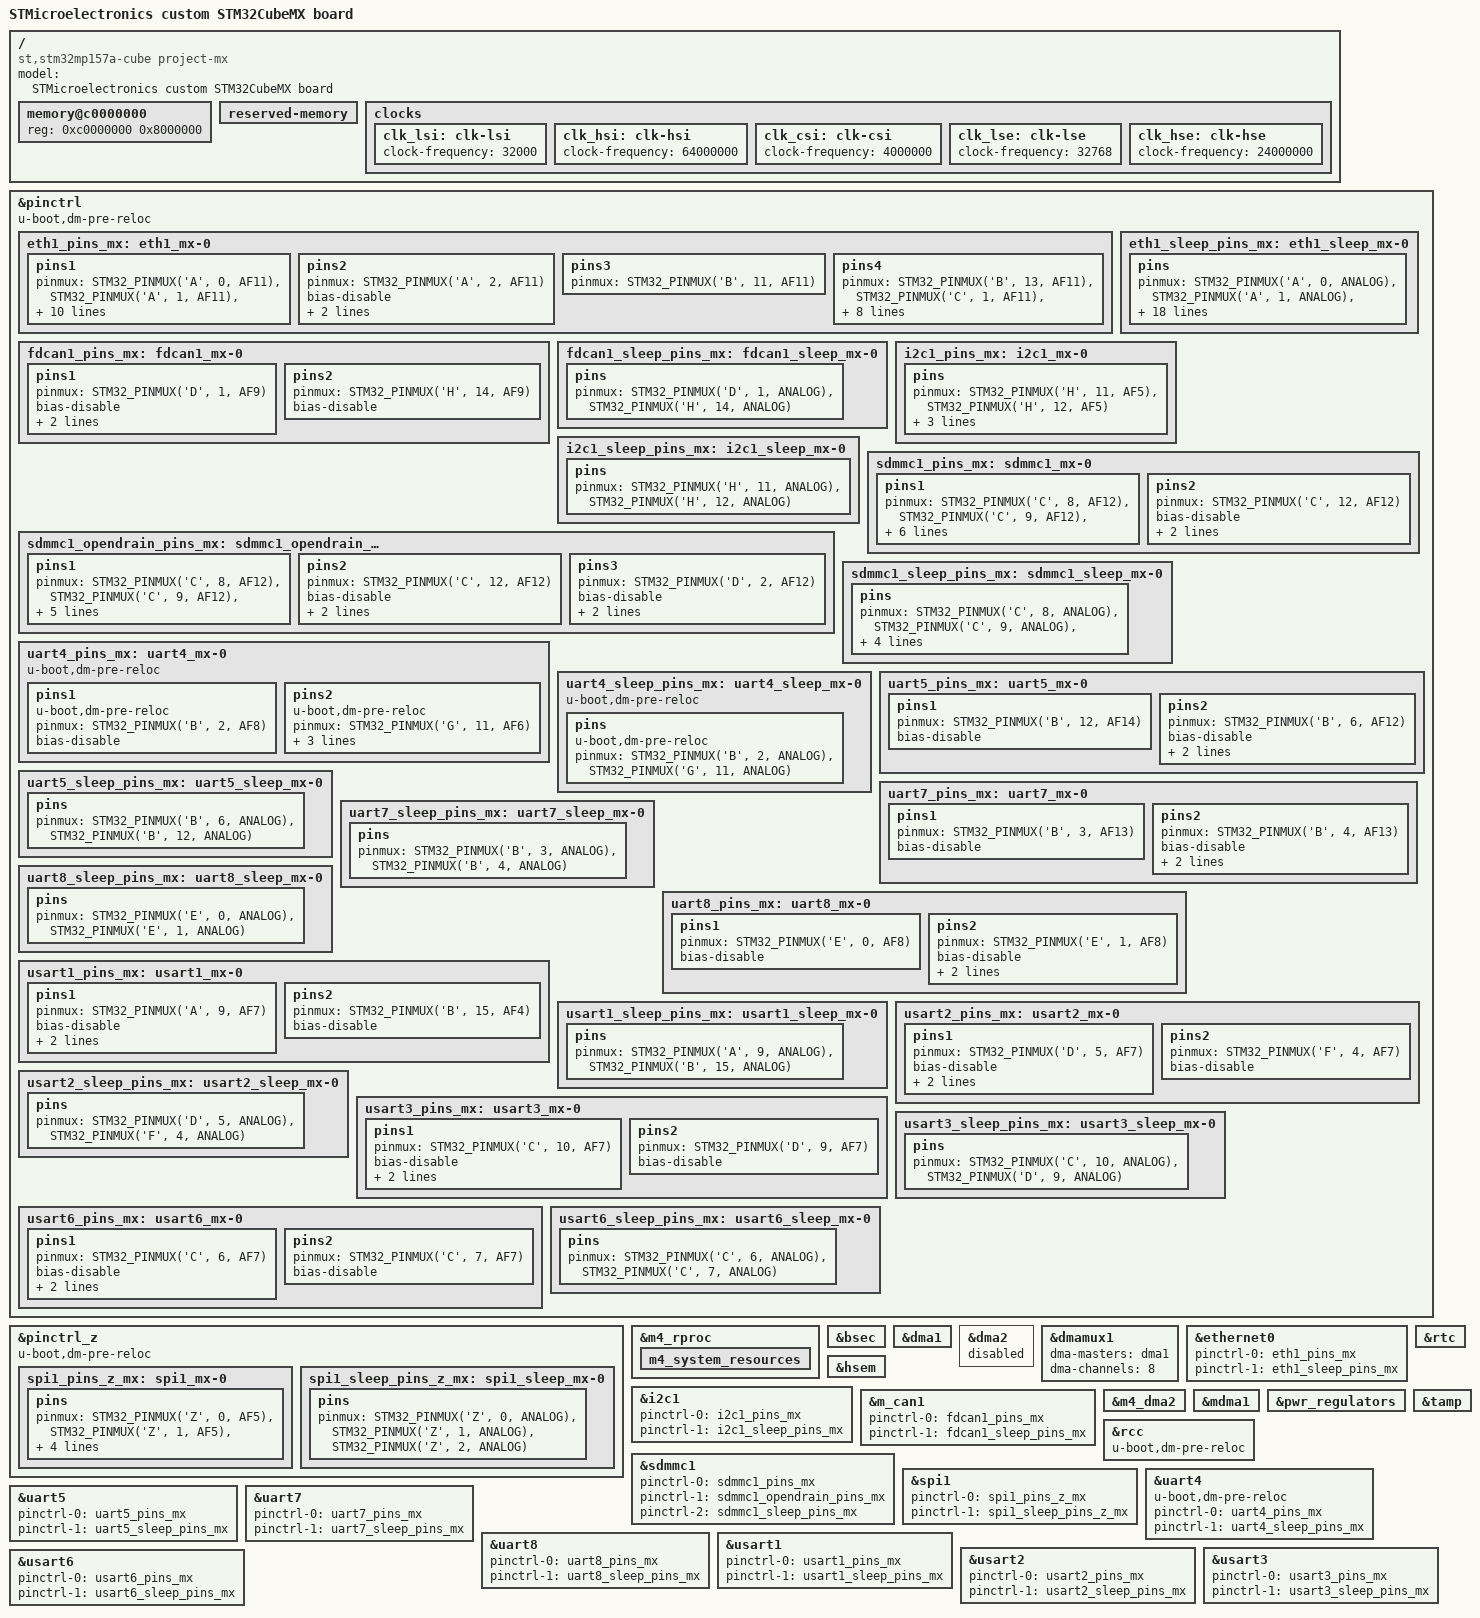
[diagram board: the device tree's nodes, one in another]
/* SPDX-License-Identifier: (GPL-2.0+ OR BSD-3-Clause) */
/*
 * Copyright (C) STMicroelectronics 2021 - All Rights Reserved
 * Author: STM32CubeMX code generation for STMicroelectronics.
 */

/* For more information on Device Tree configuration, please refer to
 * https://wiki.st.com/stm32mpu/wiki/Category:Device_tree_configuration
 */

/dts-v1/;
#include <dt-bindings/pinctrl/stm32-pinfunc.h>

#include "stm32mp157.dtsi"
#include "stm32mp15xa.dtsi"
#include "stm32mp15xxaa-pinctrl.dtsi"
#include "stm32mp157-m4-srm.dtsi"

/* USER CODE BEGIN includes */
/* USER CODE END includes */

/ {
	model = "STMicroelectronics custom STM32CubeMX board";
	compatible = "st,stm32mp157a-cube project-mx", "st,stm32mp157";

	memory@c0000000 {
		device_type = "memory";
		reg = <0xc0000000 0x8000000>;

		/* USER CODE BEGIN memory */
		/* USER CODE END memory */
	};

	reserved-memory {
		#address-cells = <1>;
		#size-cells = <1>;
		ranges;

		/* USER CODE BEGIN reserved-memory */
		/* USER CODE END reserved-memory */
	};

	/* USER CODE BEGIN root */
	/* USER CODE END root */

	clocks {
		/* USER CODE BEGIN clocks */
		/* USER CODE END clocks */

#ifndef CONFIG_STM32MP1_TRUSTED
		clk_lsi: clk-lsi {
			clock-frequency = <32000>;
		};
		clk_hsi: clk-hsi {
			clock-frequency = <64000000>;
		};
		clk_csi: clk-csi {
			clock-frequency = <4000000>;
		};
		clk_lse: clk-lse {
			clock-frequency = <32768>;
		};
		clk_hse: clk-hse {
			clock-frequency = <24000000>;
		};
#endif	/*CONFIG_STM32MP1_TRUSTED*/
	};

}; /*root*/

&pinctrl {
	u-boot,dm-pre-reloc;

	eth1_pins_mx: eth1_mx-0 {
		pins1 {
			pinmux = <STM32_PINMUX('A', 0, AF11)>, /* ETH1_CRS */
					 <STM32_PINMUX('A', 1, AF11)>, /* ETH1_RX_CLK */
					 <STM32_PINMUX('A', 3, AF11)>, /* ETH1_COL */
					 <STM32_PINMUX('A', 7, AF11)>, /* ETH1_RX_DV */
					 <STM32_PINMUX('B', 10, AF11)>, /* ETH1_RX_ER */
					 <STM32_PINMUX('C', 3, AF11)>, /* ETH1_TX_CLK */
					 <STM32_PINMUX('C', 4, AF11)>, /* ETH1_RXD0 */
					 <STM32_PINMUX('C', 5, AF11)>, /* ETH1_RXD1 */
					 <STM32_PINMUX('G', 12, AF11)>, /* ETH1_PHY_INTN */
					 <STM32_PINMUX('H', 6, AF11)>, /* ETH1_RXD2 */
					 <STM32_PINMUX('H', 7, AF11)>; /* ETH1_RXD3 */
			bias-disable;
		};
		pins2 {
			pinmux = <STM32_PINMUX('A', 2, AF11)>; /* ETH1_MDIO */
			bias-disable;
			drive-push-pull;
			slew-rate = <0>;
		};
		pins3 {
			pinmux = <STM32_PINMUX('B', 11, AF11)>; /* ETH1_TX_EN */
		};
		pins4 {
			pinmux = <STM32_PINMUX('B', 13, AF11)>, /* ETH1_TXD1 */
					 <STM32_PINMUX('C', 1, AF11)>, /* ETH1_MDC */
					 <STM32_PINMUX('C', 2, AF11)>, /* ETH1_TXD2 */
					 <STM32_PINMUX('E', 2, AF11)>, /* ETH1_TXD3 */
					 <STM32_PINMUX('F', 3, AF11)>, /* ETH1_TX_ER */
					 <STM32_PINMUX('G', 8, AF2)>, /* ETH1_CLK */
					 <STM32_PINMUX('G', 13, AF11)>; /* ETH1_TXD0 */
			bias-disable;
			drive-push-pull;
			slew-rate = <1>;
		};
	};

	eth1_sleep_pins_mx: eth1_sleep_mx-0 {
		pins {
			pinmux = <STM32_PINMUX('A', 0, ANALOG)>, /* ETH1_CRS */
					 <STM32_PINMUX('A', 1, ANALOG)>, /* ETH1_RX_CLK */
					 <STM32_PINMUX('A', 2, ANALOG)>, /* ETH1_MDIO */
					 <STM32_PINMUX('A', 3, ANALOG)>, /* ETH1_COL */
					 <STM32_PINMUX('A', 7, ANALOG)>, /* ETH1_RX_DV */
					 <STM32_PINMUX('B', 10, ANALOG)>, /* ETH1_RX_ER */
					 <STM32_PINMUX('B', 11, ANALOG)>, /* ETH1_TX_EN */
					 <STM32_PINMUX('B', 13, ANALOG)>, /* ETH1_TXD1 */
					 <STM32_PINMUX('C', 1, ANALOG)>, /* ETH1_MDC */
					 <STM32_PINMUX('C', 2, ANALOG)>, /* ETH1_TXD2 */
					 <STM32_PINMUX('C', 3, ANALOG)>, /* ETH1_TX_CLK */
					 <STM32_PINMUX('C', 4, ANALOG)>, /* ETH1_RXD0 */
					 <STM32_PINMUX('C', 5, ANALOG)>, /* ETH1_RXD1 */
					 <STM32_PINMUX('E', 2, ANALOG)>, /* ETH1_TXD3 */
					 <STM32_PINMUX('F', 3, ANALOG)>, /* ETH1_TX_ER */
					 <STM32_PINMUX('G', 8, ANALOG)>, /* ETH1_CLK */
					 <STM32_PINMUX('G', 12, ANALOG)>, /* ETH1_PHY_INTN */
					 <STM32_PINMUX('G', 13, ANALOG)>, /* ETH1_TXD0 */
					 <STM32_PINMUX('H', 6, ANALOG)>, /* ETH1_RXD2 */
					 <STM32_PINMUX('H', 7, ANALOG)>; /* ETH1_RXD3 */
		};
	};

	fdcan1_pins_mx: fdcan1_mx-0 {
		pins1 {
			pinmux = <STM32_PINMUX('D', 1, AF9)>; /* FDCAN1_TX */
			bias-disable;
			drive-push-pull;
			slew-rate = <0>;
		};
		pins2 {
			pinmux = <STM32_PINMUX('H', 14, AF9)>; /* FDCAN1_RX */
			bias-disable;
		};
	};

	fdcan1_sleep_pins_mx: fdcan1_sleep_mx-0 {
		pins {
			pinmux = <STM32_PINMUX('D', 1, ANALOG)>, /* FDCAN1_TX */
					 <STM32_PINMUX('H', 14, ANALOG)>; /* FDCAN1_RX */
		};
	};

	i2c1_pins_mx: i2c1_mx-0 {
		pins {
			pinmux = <STM32_PINMUX('H', 11, AF5)>, /* I2C1_SCL */
					 <STM32_PINMUX('H', 12, AF5)>; /* I2C1_SDA */
			bias-disable;
			drive-open-drain;
			slew-rate = <0>;
		};
	};

	i2c1_sleep_pins_mx: i2c1_sleep_mx-0 {
		pins {
			pinmux = <STM32_PINMUX('H', 11, ANALOG)>, /* I2C1_SCL */
					 <STM32_PINMUX('H', 12, ANALOG)>; /* I2C1_SDA */
		};
	};

	sdmmc1_pins_mx: sdmmc1_mx-0 {
		pins1 {
			pinmux = <STM32_PINMUX('C', 8, AF12)>, /* SDMMC1_D0 */
					 <STM32_PINMUX('C', 9, AF12)>, /* SDMMC1_D1 */
					 <STM32_PINMUX('C', 11, AF12)>, /* SDMMC1_D3 */
					 <STM32_PINMUX('D', 2, AF12)>, /* SDMMC1_CMD */
					 <STM32_PINMUX('E', 6, AF8)>; /* SDMMC1_D2 */
			bias-disable;
			drive-push-pull;
			slew-rate = <1>;
		};
		pins2 {
			pinmux = <STM32_PINMUX('C', 12, AF12)>; /* SDMMC1_CK */
			bias-disable;
			drive-push-pull;
			slew-rate = <3>;
		};
	};

	sdmmc1_opendrain_pins_mx: sdmmc1_opendrain_mx-0 {
		pins1 {
			pinmux = <STM32_PINMUX('C', 8, AF12)>, /* SDMMC1_D0 */
					 <STM32_PINMUX('C', 9, AF12)>, /* SDMMC1_D1 */
					 <STM32_PINMUX('C', 11, AF12)>, /* SDMMC1_D3 */
					 <STM32_PINMUX('E', 6, AF8)>; /* SDMMC1_D2 */
			bias-disable;
			drive-push-pull;
			slew-rate = <1>;
		};
		pins2 {
			pinmux = <STM32_PINMUX('C', 12, AF12)>; /* SDMMC1_CK */
			bias-disable;
			drive-push-pull;
			slew-rate = <3>;
		};
		pins3 {
			pinmux = <STM32_PINMUX('D', 2, AF12)>; /* SDMMC1_CMD */
			bias-disable;
			drive-open-drain;
			slew-rate = <1>;
		};
	};

	sdmmc1_sleep_pins_mx: sdmmc1_sleep_mx-0 {
		pins {
			pinmux = <STM32_PINMUX('C', 8, ANALOG)>, /* SDMMC1_D0 */
					 <STM32_PINMUX('C', 9, ANALOG)>, /* SDMMC1_D1 */
					 <STM32_PINMUX('C', 11, ANALOG)>, /* SDMMC1_D3 */
					 <STM32_PINMUX('C', 12, ANALOG)>, /* SDMMC1_CK */
					 <STM32_PINMUX('D', 2, ANALOG)>, /* SDMMC1_CMD */
					 <STM32_PINMUX('E', 6, ANALOG)>; /* SDMMC1_D2 */
		};
	};

	uart4_pins_mx: uart4_mx-0 {
		u-boot,dm-pre-reloc;
		pins1 {
			u-boot,dm-pre-reloc;
			pinmux = <STM32_PINMUX('B', 2, AF8)>; /* UART4_RX */
			bias-disable;
		};
		pins2 {
			u-boot,dm-pre-reloc;
			pinmux = <STM32_PINMUX('G', 11, AF6)>; /* UART4_TX */
			bias-disable;
			drive-push-pull;
			slew-rate = <0>;
		};
	};

	uart4_sleep_pins_mx: uart4_sleep_mx-0 {
		u-boot,dm-pre-reloc;
		pins {
			u-boot,dm-pre-reloc;
			pinmux = <STM32_PINMUX('B', 2, ANALOG)>, /* UART4_RX */
					 <STM32_PINMUX('G', 11, ANALOG)>; /* UART4_TX */
		};
	};

	uart5_pins_mx: uart5_mx-0 {
		pins1 {
			pinmux = <STM32_PINMUX('B', 12, AF14)>; /* UART5_RX */
			bias-disable;
		};
		pins2 {
			pinmux = <STM32_PINMUX('B', 6, AF12)>; /* UART5_TX */
			bias-disable;
			drive-push-pull;
			slew-rate = <0>;
		};
	};

	uart5_sleep_pins_mx: uart5_sleep_mx-0 {
		pins {
			pinmux = <STM32_PINMUX('B', 6, ANALOG)>, /* UART5_TX */
					 <STM32_PINMUX('B', 12, ANALOG)>; /* UART5_RX */
		};
	};

	uart7_pins_mx: uart7_mx-0 {
		pins1 {
			pinmux = <STM32_PINMUX('B', 3, AF13)>; /* UART7_RX */
			bias-disable;
		};
		pins2 {
			pinmux = <STM32_PINMUX('B', 4, AF13)>; /* UART7_TX */
			bias-disable;
			drive-push-pull;
			slew-rate = <0>;
		};
	};

	uart7_sleep_pins_mx: uart7_sleep_mx-0 {
		pins {
			pinmux = <STM32_PINMUX('B', 3, ANALOG)>, /* UART7_RX */
					 <STM32_PINMUX('B', 4, ANALOG)>; /* UART7_TX */
		};
	};

	uart8_pins_mx: uart8_mx-0 {
		pins1 {
			pinmux = <STM32_PINMUX('E', 0, AF8)>; /* UART8_RX */
			bias-disable;
		};
		pins2 {
			pinmux = <STM32_PINMUX('E', 1, AF8)>; /* UART8_TX */
			bias-disable;
			drive-push-pull;
			slew-rate = <0>;
		};
	};

	uart8_sleep_pins_mx: uart8_sleep_mx-0 {
		pins {
			pinmux = <STM32_PINMUX('E', 0, ANALOG)>, /* UART8_RX */
					 <STM32_PINMUX('E', 1, ANALOG)>; /* UART8_TX */
		};
	};

	usart1_pins_mx: usart1_mx-0 {
		pins1 {
			pinmux = <STM32_PINMUX('A', 9, AF7)>; /* USART1_TX */
			bias-disable;
			drive-push-pull;
			slew-rate = <0>;
		};
		pins2 {
			pinmux = <STM32_PINMUX('B', 15, AF4)>; /* USART1_RX */
			bias-disable;
		};
	};

	usart1_sleep_pins_mx: usart1_sleep_mx-0 {
		pins {
			pinmux = <STM32_PINMUX('A', 9, ANALOG)>, /* USART1_TX */
					 <STM32_PINMUX('B', 15, ANALOG)>; /* USART1_RX */
		};
	};

	usart2_pins_mx: usart2_mx-0 {
		pins1 {
			pinmux = <STM32_PINMUX('D', 5, AF7)>; /* USART2_TX */
			bias-disable;
			drive-push-pull;
			slew-rate = <0>;
		};
		pins2 {
			pinmux = <STM32_PINMUX('F', 4, AF7)>; /* USART2_RX */
			bias-disable;
		};
	};

	usart2_sleep_pins_mx: usart2_sleep_mx-0 {
		pins {
			pinmux = <STM32_PINMUX('D', 5, ANALOG)>, /* USART2_TX */
					 <STM32_PINMUX('F', 4, ANALOG)>; /* USART2_RX */
		};
	};

	usart3_pins_mx: usart3_mx-0 {
		pins1 {
			pinmux = <STM32_PINMUX('C', 10, AF7)>; /* USART3_TX */
			bias-disable;
			drive-push-pull;
			slew-rate = <0>;
		};
		pins2 {
			pinmux = <STM32_PINMUX('D', 9, AF7)>; /* USART3_RX */
			bias-disable;
		};
	};

	usart3_sleep_pins_mx: usart3_sleep_mx-0 {
		pins {
			pinmux = <STM32_PINMUX('C', 10, ANALOG)>, /* USART3_TX */
					 <STM32_PINMUX('D', 9, ANALOG)>; /* USART3_RX */
		};
	};

	usart6_pins_mx: usart6_mx-0 {
		pins1 {
			pinmux = <STM32_PINMUX('C', 6, AF7)>; /* USART6_TX */
			bias-disable;
			drive-push-pull;
			slew-rate = <0>;
		};
		pins2 {
			pinmux = <STM32_PINMUX('C', 7, AF7)>; /* USART6_RX */
			bias-disable;
		};
	};

	usart6_sleep_pins_mx: usart6_sleep_mx-0 {
		pins {
			pinmux = <STM32_PINMUX('C', 6, ANALOG)>, /* USART6_TX */
					 <STM32_PINMUX('C', 7, ANALOG)>; /* USART6_RX */
		};
	};

	/* USER CODE BEGIN pinctrl */
	/* USER CODE END pinctrl */
};

&pinctrl_z {
	u-boot,dm-pre-reloc;

	spi1_pins_z_mx: spi1_mx-0 {
		pins {
			pinmux = <STM32_PINMUX('Z', 0, AF5)>, /* SPI1_SCK */
					 <STM32_PINMUX('Z', 1, AF5)>, /* SPI1_MISO */
					 <STM32_PINMUX('Z', 2, AF5)>; /* SPI1_MOSI */
			bias-disable;
			drive-push-pull;
			slew-rate = <1>;
		};
	};

	spi1_sleep_pins_z_mx: spi1_sleep_mx-0 {
		pins {
			pinmux = <STM32_PINMUX('Z', 0, ANALOG)>, /* SPI1_SCK */
					 <STM32_PINMUX('Z', 1, ANALOG)>, /* SPI1_MISO */
					 <STM32_PINMUX('Z', 2, ANALOG)>; /* SPI1_MOSI */
		};
	};

	/* USER CODE BEGIN pinctrl_z */
	/* USER CODE END pinctrl_z */
};

&m4_rproc{
	status = "okay";

	/* USER CODE BEGIN m4_rproc */
	/* USER CODE END m4_rproc */

	m4_system_resources{
		status = "okay";

		/* USER CODE BEGIN m4_system_resources */
		/* USER CODE END m4_system_resources */
	};
};

&bsec{
	status = "okay";

	/* USER CODE BEGIN bsec */
	/* USER CODE END bsec */
};

&dma1{
	status = "okay";

	/* USER CODE BEGIN dma1 */
	/* USER CODE END dma1 */
};

&dma2{
	status = "disabled";

	/* USER CODE BEGIN dma2 */
	/* USER CODE END dma2 */
};

&dmamux1{

	dma-masters = <&dma1>;
	dma-channels = <8>;

	status = "okay";

	/* USER CODE BEGIN dmamux1 */
	/* USER CODE END dmamux1 */
};

&ethernet0{
	pinctrl-names = "default", "sleep";
	pinctrl-0 = <&eth1_pins_mx>;
	pinctrl-1 = <&eth1_sleep_pins_mx>;
	status = "okay";

	/* USER CODE BEGIN ethernet0 */
	/* USER CODE END ethernet0 */
};

&hsem{
	status = "okay";

	/* USER CODE BEGIN hsem */
	/* USER CODE END hsem */
};

&i2c1{
	pinctrl-names = "default", "sleep";
	pinctrl-0 = <&i2c1_pins_mx>;
	pinctrl-1 = <&i2c1_sleep_pins_mx>;
	status = "okay";

	/* USER CODE BEGIN i2c1 */
	/* USER CODE END i2c1 */
};

&m_can1{
	pinctrl-names = "default", "sleep";
	pinctrl-0 = <&fdcan1_pins_mx>;
	pinctrl-1 = <&fdcan1_sleep_pins_mx>;
	status = "okay";

	/* USER CODE BEGIN m_can1 */
	/* USER CODE END m_can1 */
};

&m4_dma2{
	status = "okay";

	/* USER CODE BEGIN m4_dma2 */
	/* USER CODE END m4_dma2 */
};

&mdma1{
	status = "okay";

	/* USER CODE BEGIN mdma1 */
	/* USER CODE END mdma1 */
};

&pwr_regulators{
	status = "okay";

	/* USER CODE BEGIN pwr_regulators */
	/* USER CODE END pwr_regulators */
};

&rcc{
	u-boot,dm-pre-reloc;
	status = "okay";

	/* USER CODE BEGIN rcc */
	/* USER CODE END rcc */
};

&rtc{
	status = "okay";

	/* USER CODE BEGIN rtc */
	/* USER CODE END rtc */
};

&sdmmc1{
	pinctrl-names = "default", "opendrain", "sleep";
	pinctrl-0 = <&sdmmc1_pins_mx>;
	pinctrl-1 = <&sdmmc1_opendrain_pins_mx>;
	pinctrl-2 = <&sdmmc1_sleep_pins_mx>;
	status = "okay";

	/* USER CODE BEGIN sdmmc1 */
	/* USER CODE END sdmmc1 */
};

&spi1{
	pinctrl-names = "default", "sleep";
	pinctrl-0 = <&spi1_pins_z_mx>;
	pinctrl-1 = <&spi1_sleep_pins_z_mx>;
	status = "okay";

	/* USER CODE BEGIN spi1 */
	/* USER CODE END spi1 */
};

&tamp{
	status = "okay";

	/* USER CODE BEGIN tamp */
	/* USER CODE END tamp */
};

&uart4{
	u-boot,dm-pre-reloc;
	pinctrl-names = "default", "sleep";
	pinctrl-0 = <&uart4_pins_mx>;
	pinctrl-1 = <&uart4_sleep_pins_mx>;
	status = "okay";

	/* USER CODE BEGIN uart4 */
	/* USER CODE END uart4 */
};

&uart5{
	pinctrl-names = "default", "sleep";
	pinctrl-0 = <&uart5_pins_mx>;
	pinctrl-1 = <&uart5_sleep_pins_mx>;
	status = "okay";

	/* USER CODE BEGIN uart5 */
	/* USER CODE END uart5 */
};

&uart7{
	pinctrl-names = "default", "sleep";
	pinctrl-0 = <&uart7_pins_mx>;
	pinctrl-1 = <&uart7_sleep_pins_mx>;
	status = "okay";

	/* USER CODE BEGIN uart7 */
	/* USER CODE END uart7 */
};

&uart8{
	pinctrl-names = "default", "sleep";
	pinctrl-0 = <&uart8_pins_mx>;
	pinctrl-1 = <&uart8_sleep_pins_mx>;
	status = "okay";

	/* USER CODE BEGIN uart8 */
	/* USER CODE END uart8 */
};

&usart1{
	pinctrl-names = "default", "sleep";
	pinctrl-0 = <&usart1_pins_mx>;
	pinctrl-1 = <&usart1_sleep_pins_mx>;
	status = "okay";

	/* USER CODE BEGIN usart1 */
	/* USER CODE END usart1 */
};

&usart2{
	pinctrl-names = "default", "sleep";
	pinctrl-0 = <&usart2_pins_mx>;
	pinctrl-1 = <&usart2_sleep_pins_mx>;
	status = "okay";

	/* USER CODE BEGIN usart2 */
	/* USER CODE END usart2 */
};

&usart3{
	pinctrl-names = "default", "sleep";
	pinctrl-0 = <&usart3_pins_mx>;
	pinctrl-1 = <&usart3_sleep_pins_mx>;
	status = "okay";

	/* USER CODE BEGIN usart3 */
	/* USER CODE END usart3 */
};

&usart6{
	pinctrl-names = "default", "sleep";
	pinctrl-0 = <&usart6_pins_mx>;
	pinctrl-1 = <&usart6_sleep_pins_mx>;
	status = "okay";

	/* USER CODE BEGIN usart6 */
	/* USER CODE END usart6 */
};

/* USER CODE BEGIN addons */
/* USER CODE END addons */

